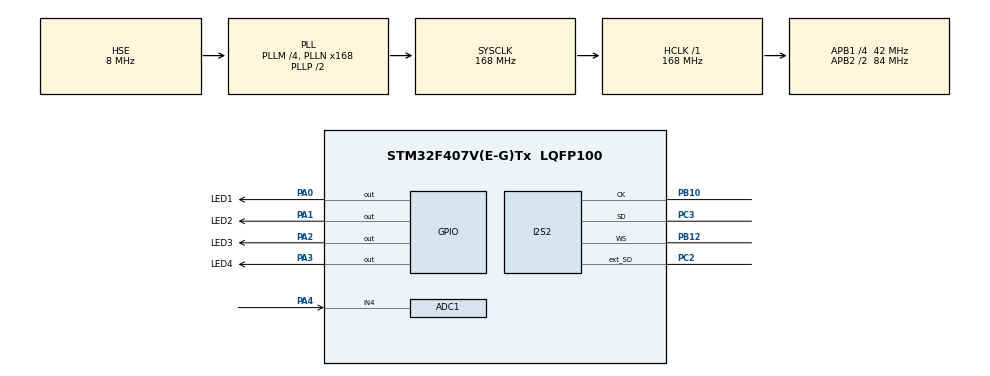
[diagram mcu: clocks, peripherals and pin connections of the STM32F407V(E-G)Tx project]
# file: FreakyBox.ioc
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ADC1.Channel-0\#ChannelRegularConversion=ADC_CHANNEL_4
ADC1.NbrOfConversionFlag=1
ADC1.Rank-0\#ChannelRegularConversion=1
ADC1.SamplingTime-0\#ChannelRegularConversion=ADC_SAMPLETIME_3CYCLES
ADC1.master=1
Dma.Request0=SPI2_TX
Dma.SPI2_TX.0.Direction=DMA_MEMORY_TO_PERIPH
Dma.SPI2_TX.0.FIFOMode=DMA_FIFOMODE_DISABLE
Dma.SPI2_TX.0.Instance=DMA1_Stream4
Dma.SPI2_TX.0.MemDataAlignment=DMA_MDATAALIGN_HALFWORD
Dma.SPI2_TX.0.MemInc=DMA_MINC_ENABLE
Dma.SPI2_TX.0.Mode=DMA_CIRCULAR
Dma.SPI2_TX.0.PeriphDataAlignment=DMA_PDATAALIGN_HALFWORD
Dma.SPI2_TX.0.PeriphInc=DMA_PINC_DISABLE
Dma.SPI2_TX.0.Priority=DMA_PRIORITY_VERY_HIGH
I2S2.AudioFreq=I2S_AUDIOFREQ_48K
I2S2.ErrorAudioFreq=0.0 %
I2S2.FullDuplexMode=I2S_FULLDUPLEXMODE_ENABLE
I2S2.Instance=SPI$Index
I2S2.RealAudioFreq=48.0 KHz
I2S2.VirtualMode=I2S_MODE_MASTER
Mcu.Family=STM32F4
Mcu.Name=STM32F407V(E-G)Tx
Mcu.Package=LQFP100
NVIC.DMA1_Stream4_IRQn=true\:0\:0\:false\:false\:true\:false\:true\:true
NVIC.PriorityGroup=NVIC_PRIORITYGROUP_4
NVIC.TIM2_IRQn=true\:0\:0\:false\:false\:true\:true\:true\:true
PA0-WKUP.GPIO_Label=LED1
PA0-WKUP.GPIO_Speed=GPIO_SPEED_FREQ_VERY_HIGH
PA0-WKUP.Signal=GPIO_Output
PA1.GPIO_Label=LED2
PA1.GPIO_Speed=GPIO_SPEED_FREQ_VERY_HIGH
PA1.Signal=GPIO_Output
PA2.GPIO_Label=LED3
PA2.GPIO_Speed=GPIO_SPEED_FREQ_VERY_HIGH
PA2.Signal=GPIO_Output
PA3.GPIO_Label=LED4
PA3.GPIO_Speed=GPIO_SPEED_FREQ_VERY_HIGH
PA3.Signal=GPIO_Output
PA4.Signal=ADCx_IN4
PB10.Mode=Full_Duplex_Master
PB10.Signal=I2S2_CK
PB12.Mode=Full_Duplex_Master
PB12.Signal=I2S2_WS
PC2.Mode=Full_Duplex_Master
PC2.Signal=I2S2_ext_SD
PC3.Mode=Full_Duplex_Master
PC3.Signal=I2S2_SD
PH0-OSC_IN.Mode=HSE-External-Oscillator
PH0-OSC_IN.Signal=RCC_OSC_IN
PH1-OSC_OUT.Mode=HSE-External-Oscillator
PH1-OSC_OUT.Signal=RCC_OSC_OUT
ProjectManager.HeapSize=0x200
ProjectManager.StackSize=0x400
ProjectManager.TargetToolchain=STM32CubeIDE
RCC.48MHZClocksFreq_Value=84000000
RCC.AHBFreq_Value=168000000
RCC.APB1CLKDivider=RCC_HCLK_DIV4
RCC.APB1Freq_Value=42000000
RCC.APB1TimFreq_Value=84000000
RCC.APB2CLKDivider=RCC_HCLK_DIV2
RCC.APB2Freq_Value=84000000
RCC.APB2TimFreq_Value=168000000
RCC.CortexFreq_Value=168000000
RCC.HCLKFreq_Value=168000000
RCC.HSE_VALUE=8000000
RCC.HSI_VALUE=16000000
RCC.LSE_VALUE=32768
RCC.PLLM=4
RCC.PLLN=168
RCC.PLLSourceVirtual=RCC_PLLSOURCE_HSE
RCC.SYSCLKFreq_VALUE=168000000
RCC.SYSCLKSource=RCC_SYSCLKSOURCE_PLLCLK
RCC.VCOOutputFreq_Value=336000000
SH.ADCx_IN4.0=ADC1_IN4,IN4
TIM2.Period=9999
TIM2.Prescaler=8399
VP_TIM2_VS_ClockSourceINT.Mode=Internal
board=custom

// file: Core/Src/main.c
/* USER CODE BEGIN Header */
/**
  ******************************************************************************
  * @file           : main.c
  * @brief          : Main program body
  ******************************************************************************
  * @attention
  *
  * Copyright (c) 2025 STMicroelectronics.
  * All rights reserved.
  *
  * This software is licensed under terms that can be found in the LICENSE file
  * in the root directory of this software component.
  * If no LICENSE file comes with this software, it is provided AS-IS.
  *
  ******************************************************************************
  */
/* USER CODE END Header */
#include "main.h"

ADC_HandleTypeDef hadc1;

I2S_HandleTypeDef hi2s2;
DMA_HandleTypeDef hdma_spi2_tx;

TIM_HandleTypeDef htim2;

/* USER CODE BEGIN PV */
int16_t audio_buffer[BUFFER_SIZE];
int16_t *audio_buffer_ptr = &audio_buffer[0];
CallBacksEnum callback_return = DMA_STARTED;
/* USER CODE END PV */

void SystemClock_Config(void);
static void MX_GPIO_Init(void);
static void MX_DMA_Init(void);
static void MX_TIM2_Init(void);
static void MX_I2S2_Init(void);
static void MX_ADC1_Init(void);

/* USER CODE BEGIN 0 */
void HAL_I2S_TxHalfCpltCallback(I2S_HandleTypeDef *hi2s3)
{
	callback_return = DMA_HALF_COMPLETED;
}

void HAL_I2S_TxCpltCallback(I2S_HandleTypeDef *hi2s3)
{
	callback_return = DMA_COMPLETED;
}
/* USER CODE END 0 */

int main(void)
{

  /* MCU Configuration--------------------------------------------------------*/

  /* Reset of all peripherals, Initializes the Flash interface and the Systick. */
  HAL_Init();

  /* Configure the system clock */
  SystemClock_Config();

  /* Initialize all configured peripherals */
  MX_GPIO_Init();
  MX_DMA_Init();
  MX_TIM2_Init();
  MX_I2S2_Init();
  MX_ADC1_Init();
  /* USER CODE BEGIN 2 */
  HAL_TIM_Base_Start_IT(&htim2);
  HAL_StatusTypeDef DMA_TX_Status = HAL_I2S_Transmit_DMA(&hi2s2, (uint16_t *)audio_buffer, SAMPLE_RATE);
  /* USER CODE END 2 */

  /* Infinite loop */
  /* USER CODE BEGIN WHILE */
  while (1)
  {
	  mcuMain();
    /* USER CODE END WHILE */

  }
}

void SystemClock_Config(void)
{
  RCC_OscInitTypeDef RCC_OscInitStruct = {0};
  RCC_ClkInitTypeDef RCC_ClkInitStruct = {0};

  /** Configure the main internal regulator output voltage
  */
  __HAL_RCC_PWR_CLK_ENABLE();
  __HAL_PWR_VOLTAGESCALING_CONFIG(PWR_REGULATOR_VOLTAGE_SCALE1);

  /** Initializes the RCC Oscillators according to the specified parameters
  * in the RCC_OscInitTypeDef structure.
  */
  RCC_OscInitStruct.OscillatorType = RCC_OSCILLATORTYPE_HSE;
  RCC_OscInitStruct.HSEState = RCC_HSE_ON;
  RCC_OscInitStruct.PLL.PLLState = RCC_PLL_ON;
  RCC_OscInitStruct.PLL.PLLSource = RCC_PLLSOURCE_HSE;
  RCC_OscInitStruct.PLL.PLLM = 4;
  RCC_OscInitStruct.PLL.PLLN = 168;
  RCC_OscInitStruct.PLL.PLLP = RCC_PLLP_DIV2;
  RCC_OscInitStruct.PLL.PLLQ = 4;
  if (HAL_RCC_OscConfig(&RCC_OscInitStruct) != HAL_OK)
  {
    Error_Handler();
  }

  /** Initializes the CPU, AHB and APB buses clocks
  */
  RCC_ClkInitStruct.ClockType = RCC_CLOCKTYPE_HCLK|RCC_CLOCKTYPE_SYSCLK
                              |RCC_CLOCKTYPE_PCLK1|RCC_CLOCKTYPE_PCLK2;
  RCC_ClkInitStruct.SYSCLKSource = RCC_SYSCLKSOURCE_PLLCLK;
  RCC_ClkInitStruct.AHBCLKDivider = RCC_SYSCLK_DIV1;
  RCC_ClkInitStruct.APB1CLKDivider = RCC_HCLK_DIV4;
  RCC_ClkInitStruct.APB2CLKDivider = RCC_HCLK_DIV2;

  if (HAL_RCC_ClockConfig(&RCC_ClkInitStruct, FLASH_LATENCY_5) != HAL_OK)
  {
    Error_Handler();
  }
}

static void MX_ADC1_Init(void)
{

  ADC_ChannelConfTypeDef sConfig = {0};

  /** Configure the global features of the ADC (Clock, Resolution, Data Alignment and number of conversion)
  */
  hadc1.Instance = ADC1;
  hadc1.Init.ClockPrescaler = ADC_CLOCK_SYNC_PCLK_DIV4;
  hadc1.Init.Resolution = ADC_RESOLUTION_12B;
  hadc1.Init.ScanConvMode = DISABLE;
  hadc1.Init.ContinuousConvMode = DISABLE;
  hadc1.Init.DiscontinuousConvMode = DISABLE;
  hadc1.Init.ExternalTrigConvEdge = ADC_EXTERNALTRIGCONVEDGE_NONE;
  hadc1.Init.ExternalTrigConv = ADC_SOFTWARE_START;
  hadc1.Init.DataAlign = ADC_DATAALIGN_RIGHT;
  hadc1.Init.NbrOfConversion = 1;
  hadc1.Init.DMAContinuousRequests = DISABLE;
  hadc1.Init.EOCSelection = ADC_EOC_SINGLE_CONV;
  if (HAL_ADC_Init(&hadc1) != HAL_OK)
  {
    Error_Handler();
  }

  /** Configure for the selected ADC regular channel its corresponding rank in the sequencer and its sample time.
  */
  sConfig.Channel = ADC_CHANNEL_4;
  sConfig.Rank = 1;
  sConfig.SamplingTime = ADC_SAMPLETIME_3CYCLES;
  if (HAL_ADC_ConfigChannel(&hadc1, &sConfig) != HAL_OK)
  {
    Error_Handler();
  }

}

static void MX_I2S2_Init(void)
{

  hi2s2.Instance = SPI2;
  hi2s2.Init.Mode = I2S_MODE_MASTER_TX;
  hi2s2.Init.Standard = I2S_STANDARD_PHILIPS;
  hi2s2.Init.DataFormat = I2S_DATAFORMAT_16B;
  hi2s2.Init.MCLKOutput = I2S_MCLKOUTPUT_DISABLE;
  hi2s2.Init.AudioFreq = I2S_AUDIOFREQ_48K;
  hi2s2.Init.CPOL = I2S_CPOL_LOW;
  hi2s2.Init.ClockSource = I2S_CLOCK_PLL;
  hi2s2.Init.FullDuplexMode = I2S_FULLDUPLEXMODE_ENABLE;
  if (HAL_I2S_Init(&hi2s2) != HAL_OK)
  {
    Error_Handler();
  }

}

static void MX_TIM2_Init(void)
{

  TIM_ClockConfigTypeDef sClockSourceConfig = {0};
  TIM_MasterConfigTypeDef sMasterConfig = {0};

  htim2.Instance = TIM2;
  htim2.Init.Prescaler = 8399;
  htim2.Init.CounterMode = TIM_COUNTERMODE_UP;
  htim2.Init.Period = 9999;
  htim2.Init.ClockDivision = TIM_CLOCKDIVISION_DIV1;
  htim2.Init.AutoReloadPreload = TIM_AUTORELOAD_PRELOAD_DISABLE;
  if (HAL_TIM_Base_Init(&htim2) != HAL_OK)
  {
    Error_Handler();
  }
  sClockSourceConfig.ClockSource = TIM_CLOCKSOURCE_INTERNAL;
  if (HAL_TIM_ConfigClockSource(&htim2, &sClockSourceConfig) != HAL_OK)
  {
    Error_Handler();
  }
  sMasterConfig.MasterOutputTrigger = TIM_TRGO_RESET;
  sMasterConfig.MasterSlaveMode = TIM_MASTERSLAVEMODE_DISABLE;
  if (HAL_TIMEx_MasterConfigSynchronization(&htim2, &sMasterConfig) != HAL_OK)
  {
    Error_Handler();
  }

}

static void MX_DMA_Init(void)
{

  /* DMA controller clock enable */
  __HAL_RCC_DMA1_CLK_ENABLE();

  /* DMA interrupt init */
  /* DMA1_Stream4_IRQn interrupt configuration */
  HAL_NVIC_SetPriority(DMA1_Stream4_IRQn, 0, 0);
  HAL_NVIC_EnableIRQ(DMA1_Stream4_IRQn);

}

static void MX_GPIO_Init(void)
{
  GPIO_InitTypeDef GPIO_InitStruct = {0};

  /* GPIO Ports Clock Enable */
  __HAL_RCC_GPIOH_CLK_ENABLE();
  __HAL_RCC_GPIOC_CLK_ENABLE();
  __HAL_RCC_GPIOA_CLK_ENABLE();
  __HAL_RCC_GPIOB_CLK_ENABLE();

  /*Configure GPIO pin Output Level */
  HAL_GPIO_WritePin(GPIOA, LED1_Pin|LED2_Pin|LED3_Pin|LED4_Pin, GPIO_PIN_RESET);

  /*Configure GPIO pins : LED1_Pin LED2_Pin LED3_Pin LED4_Pin */
  GPIO_InitStruct.Pin = LED1_Pin|LED2_Pin|LED3_Pin|LED4_Pin;
  GPIO_InitStruct.Mode = GPIO_MODE_OUTPUT_PP;
  GPIO_InitStruct.Pull = GPIO_NOPULL;
  GPIO_InitStruct.Speed = GPIO_SPEED_FREQ_VERY_HIGH;
  HAL_GPIO_Init(GPIOA, &GPIO_InitStruct);

}

void Error_Handler(void)
{
  __disable_irq();
  while (1)
  {
  }
}
